# STM32H7S register map
File version: 1.3
CPU: CM7 r0p1, little endian, MPU, FPU, 4 interrupt priority bits
Registers are 32-bit, read-write, reset 0x0 unless marked. A register's access mark holds for its fields unless they carry their own. Offsets are from the block's base; [hi:lo] are bit positions; {n}, {i} and the like mark numbered series.

## TIM16 — General purpose timers
Base 0x42004400
Same registers: TIM17 0x42004800
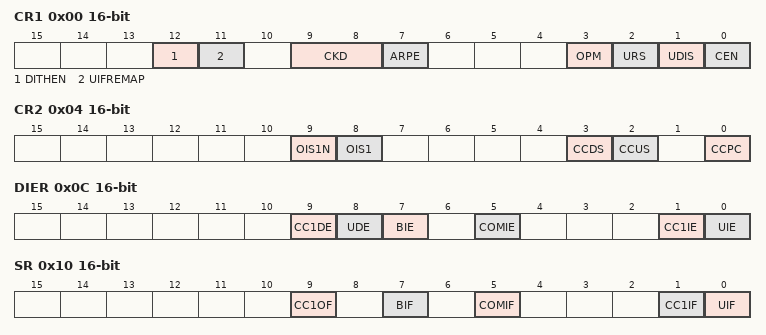
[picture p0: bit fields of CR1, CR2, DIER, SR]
0x00 CR1 16-bit — TIM16 control register 1
  [12] DITHEN — Dithering enable Note: The DITHEN bit can only be modified when CEN bit is reset.
    0=Disabled (Dithering disabled); 1=Enabled (Dithering enabled)
  [11] UIFREMAP — UIF status bit remapping
    0=Disabled (No remapping. UIF status bit is not copied to TIMx_CNT register bit 31); 1=Enabled (Remapping enabled. UIF status bit is copied to TIMx_CNT register bit 31)
  [9:8] CKD — Clock division This bit-field indicates the division ratio between the timer clock (tim_ker_ck) frequency and the dead-time and sampling clock (t<sub>DTS</sub>)used by the dead-time generators and the digital filters (tim_tix),
    0=Div1 (t_DTS = t_CK_INT); 1=Div2 (t_DTS = 2 × t_CK_INT); 2=Div4 (t_DTS = 4 × t_CK_INT)
  [7] ARPE — Auto-reload preload enable
    0=Disabled (TIMx_APRR register is not buffered); 1=Enabled (TIMx_APRR register is buffered)
  [3] OPM — One pulse mode
    0=Disabled (Counter is not stopped at update event); 1=Enabled (Counter stops counting at the next update event (clearing the CEN bit))
  [2] URS — Update request source This bit is set and cleared by software to select the UEV event sources. Counter overflow/underflow Setting the UG bit Update generation through the slave mode controller
    0=AnyEvent (Any of counter overflow/underflow, setting UG, or update through slave mode, generates an update interrupt or DMA request); 1=CounterOnly (Only counter overflow/underflow generates an update interrupt or DMA request)
  [1] UDIS — Update disable This bit is set and cleared by software to enable/disable UEV event generation. Counter overflow/underflow Setting the UG bit Update generation through the slave mode controller Buffered registers are then loaded with their preload values.
    0=Enabled (Update event enabled); 1=Disabled (Update event disabled)
  [0] CEN — Counter enable Note: External clock and gated mode can work only if the CEN bit has been previously set by software. However trigger mode can set the CEN bit automatically by hardware.
    0=Disabled (Counter disabled); 1=Enabled (Counter enabled)
0x04 CR2 16-bit — TIM16 control register 2
  [n+8] OIS{n}N (n=1..1) — Output Idle state (OC{n}N output)
    0=Reset (OCxN=0 after a dead-time when MOE=0); 1=Set (OCxN=1 after a dead-time when MOE=0)
  [n+7] OIS{n} (n=1..1) — Output Idle state (OC{n} output)
    0=Reset (OCx=0 (after a dead-time if OCx(N) is implemented) when MOE=0); 1=Set (OCx=1 (after a dead-time if OCx(N) is implemented) when MOE=0)
  [3] CCDS — Capture/compare DMA selection
    0=OnCompare (CCx DMA request sent when CCx event occurs); 1=OnUpdate (CCx DMA request sent when update event occurs)
  [2] CCUS — Capture/compare control update selection Note: This bit acts only on channels that have a complementary output.
    0=Sw (When capture/compare control bits are preloaded (CCPC=1), they are updated by setting the COMG bit only); 1=SwOrEdge (When capture/compare control bits are preloaded (CCPC=1), they are updated by setting the COMG bit or when an rising edge occurs on TRGI)
  [0] CCPC — Capture/compare preloaded control Note: This bit acts only on channels that have a complementary output.
    0=NotPreloaded (CCxE, CCxNE and OCxM bits are not preloaded); 1=Preloaded (CCxE, CCxNE and OCxM bits are preloaded)
0x0C DIER 16-bit — TIM16 DMA/interrupt enable register
  [n+8] CC{n}DE (n=1..1) — Capture/Compare {n} DMA request enable
    0=Disabled (CCx DMA request disabled); 1=Enabled (CCx DMA request enabled)
  [8] UDE — Update DMA request enable
    0=Disabled (Update DMA request disabled); 1=Enabled (Update DMA request enabled)
  [7] BIE — Break interrupt enable
    0=Disabled (Break interrupt disabled); 1=Enabled (Break interrupt enabled)
  [5] COMIE — COM interrupt enable
    0=Disabled (COM interrupt disabled); 1=Enabled (COM interrupt enabled)
  [n] CC{n}IE (n=1..1) — Capture/Compare {n} interrupt enable
    0=Disabled (CCx interrupt disabled); 1=Enabled (CCx interrupt enabled)
  [0] UIE — Update interrupt enable
    0=Disabled (Update interrupt disabled); 1=Enabled (Update interrupt enabled)
0x10 SR 16-bit — TIM16 status register
  [n+8] CC{n}OF (n=1..1) write-0-clears — Capture/Compare {n} overcapture flag
    on read: 0=No overcapture has been detected; 1=Overcapture (The counter value has been captured in TIMx_CCRx register while CCxIF flag was already set) | on write: 0=Clear flag
  [7] BIF write-0-clears — Break interrupt flag This flag is set by hardware as soon as the tim_brk input goes active. It can be cleared by software if the break input is not active.
    on read: 0=NoTrigger (No break event occurred); 1=Trigger (An active level has been detected on the break input. An interrupt is generated if BIE=1 in the TIMx_DIER register) | on write: 0=Clear flag
  [5] COMIF write-0-clears — COM interrupt flag This flag is set by hardware on a COM event (once the capture/compare control bits CCxE, CCxNE, OCxM have been updated). It is cleared by software.
    on read: 0=No COM event occurred; 1=COM (COM interrupt pending) | on write: 0=Clear flag
  [n] CC{n}IF (n=1..1) write-0-clears — Capture/compare {n} interrupt flag
    on read: 0=NoMatch (No campture/compare has been detected); 1=Match (If CC1 is an output: The content of the counter TIMx_CNT matches the content of the TIMx_CCR1 register. If CC1 is an input: The counter value has been captured in TIMx_CCR1 register.) | on write: 0=Clear flag
  [0] UIF write-0-clears — Update interrupt flag This bit is set by hardware on an update event. It is cleared by software. At overflow regarding the repetition counter value (update if repetition counter = 0) and if the UDIS=0 in the TIMx_CR1 register. When CNT is reinitialized by software using the UG bit in TIMx_EGR register, if URS=0 and UDIS=0 in the TIMx_CR1 register.
    on read: 0=NoUpdateOccurred; 1=UpdatePending (Update interrupt pending) | on write: 0=Clear flag
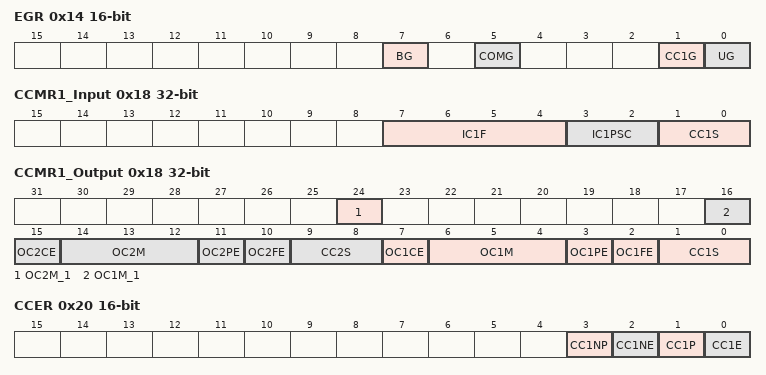
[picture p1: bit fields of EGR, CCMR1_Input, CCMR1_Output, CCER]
0x14 EGR 16-bit wo — TIM16 event generation register
  [7] BG — Break generation This bit is set by software in order to generate an event, it is automatically cleared by hardware.
    1=Trigger (A break event is generated. MOE bit is cleared and BIF flag is set. Related interrupt or DMA transfer can occur if enabled)
  [5] COMG — Capture/Compare control update generation This bit can be set by software, it is automatically cleared by hardware. Note: This bit acts only on channels that have a complementary output.
    1=Trigger (When CCPC bit is set, it allows CCxE, CCxNE and OCxM bits to be updated)
  [n] CC{n}G (n=1..1) — Capture/compare {n} generation
    1=Trigger (If CC1 is an output: CC1IF flag is set, Corresponding interrupt or DMA request is sent if enabled. If CC1 is an input: The current value of the counter is captured in TIMx_CCR1 register.)
  [0] UG — Update generation This bit can be set by software, it is automatically cleared by hardware.
    1=Update (Re-initializes the timer counter and generates an update of the registers.)
0x18 CCMR1_Input — TIM16 capture/compare mode register 1
  [n+6:n+3] IC{n}F (n=1..1) — Input capture {n} filter
    0=No filter, sampling is done at fDTS; 1=FCK_INT_N2 (fSAMPLING=fCK_INT, N=2); 2=FCK_INT_N4 (fSAMPLING=fCK_INT, N=4); 3=FCK_INT_N8 (fSAMPLING=fCK_INT, N=8); 4=FDTS_Div2_N6 (fSAMPLING=fDTS/2, N=6); 5=FDTS_Div2_N8 (fSAMPLING=fDTS/2, N=8); 6=FDTS_Div4_N6 (fSAMPLING=fDTS/4, N=6); 7=FDTS_Div4_N8 (fSAMPLING=fDTS/4, N=8); 8=FDTS_Div8_N6 (fSAMPLING=fDTS/8, N=6); 9=FDTS_Div8_N8 (fSAMPLING=fDTS/8, N=8); 10=FDTS_Div16_N5 (fSAMPLING=fDTS/16, N=5); 11=FDTS_Div16_N6 (fSAMPLING=fDTS/16, N=6); 12=FDTS_Div16_N8 (fSAMPLING=fDTS/16, N=8); 13=FDTS_Div32_N5 (fSAMPLING=fDTS/32, N=5); 14=FDTS_Div32_N6 (fSAMPLING=fDTS/32, N=6); 15=FDTS_Div32_N8 (fSAMPLING=fDTS/32, N=8)
  [n+2:n+1] IC{n}PSC (n=1..1) — Input capture {n} prescaler
    0=No prescaler, capture is done each time an edge is detected on the capture input; 1=TwoEvents (Capture is done once every 2 events); 2=FourEvents (Capture is done once every 4 events); 3=EightEvents (Capture is done once every 8 events)
  [1:0] CC1S — Capture/Compare 1 selection This bit-field defines the direction of the channel (input/output) as well as the used input. Others: Reserved Note: CC1S bits are writable only when the channel is OFF (CC1E = 0 in TIMx_CCER).
    1=TI1 (CC1 channel is configured as input, IC1 is mapped on TI1)
0x18 CCMR1_Output (alternate view of CCMR1_Input) — TIM16 capture/compare mode register 1 [alternate]
  [24] OC2M_1 — OC2M[3]
  [16] OC1M_1 — OC1M[3]
  [8n-1] OC{n}CE (n=1..2) — Output compare {n} clear enable
    0=Disabled (OCxRef is not affected by the ocref_clr_int signal); 1=Enabled (OCxRef is cleared as soon as a High level is detected on ocref_clr_int signal)
  [8n-2:8n-4] OC{n}M (n=1..2) — Output compare {n} mode
    0=Frozen (The comparison between the output compare register TIMx_CCRy and the counter TIMx_CNT has no effect on the outputs); 1=ActiveOnMatch (Set channel to active level on match. OCyREF signal is forced high when the counter matches the capture/compare register); 2=InactiveOnMatch (Set channel to inactive level on match. OCyREF signal is forced low when the counter matches the capture/compare register); 3=Toggle (OCyREF toggles when TIMx_CNT=TIMx_CCRy); 4=ForceInactive (OCyREF is forced low); 5=ForceActive (OCyREF is forced high); 6=PwmMode1 (In upcounting, channel is active as long as TIMx_CNT<TIMx_CCRy else inactive. In downcounting, channel is inactive as long as TIMx_CNT>TIMx_CCRy else active); 7=PwmMode2 (Inversely to PwmMode1)
  [8n-5] OC{n}PE (n=1..2) — Output compare {n} preload enable
    0=Disabled (Preload register on CCRx disabled. New values written to CCRx are taken into account immediately); 1=Enabled (Preload register on CCRx enabled. Preload value is loaded into active register on each update event)
  [8n-6] OC{n}FE (n=1..2) — Output compare {n} fast enable
    0=Disabled (Fast output disabled); 1=Enabled (Fast output enabled)
  [8n-7:8n-8] CC{n}S (n=1..2) — Capture/Compare {n} selection
    0=Output (CCx channel is configured as output)
0x20 CCER 16-bit — TIM16 capture/compare enable register
  [n+2] CC{n}NP (n=1..1) — Capture/Compare {n} output Polarity
    0=ActiveHigh (OCxN active high); 1=ActiveLow (OCxN active low)
  [n+1] CC{n}NE (n=1..1) — Capture/Compare {n} complementary output enable
    0=Disabled (Complementary output disabled); 1=Enabled (Complementary output enabled)
  [n] CC{n}P (n=1..1) — Capture/Compare {n} output Polarity
    0=RisingEdge (Noninverted/rising edge); 1=FallingEdge (Inverted/falling edge)
  [n-1] CC{n}E (n=1..1) — Capture/Compare {n} output enable
    0=Disabled (Capture disabled); 1=Enabled (Capture enabled)
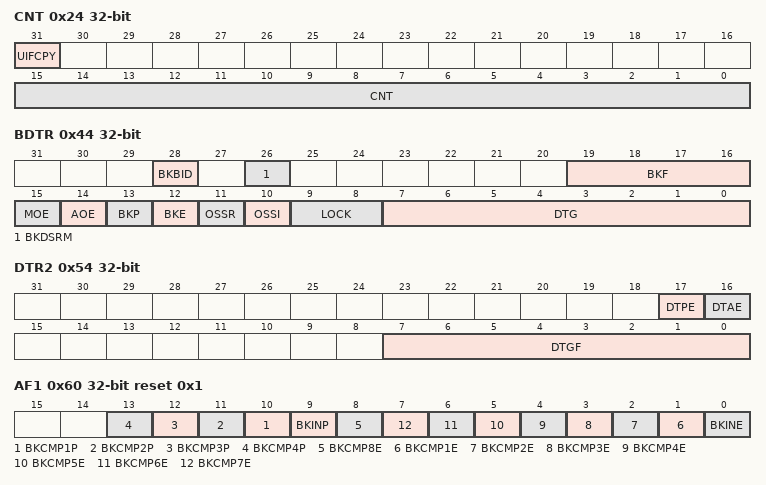
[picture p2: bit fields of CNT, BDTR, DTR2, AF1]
0x24 CNT access per field — TIM16 counter
  [31] UIFCPY ro — UIF Copy This bit is a read-only copy of the UIF bit of the TIMx_ISR register. If the UIFREMAP bit in TIMx_CR1 is reset, bit 31 is reserved.
    0=NoUpdateOccurred; 1=UpdatePending (Update interrupt pending)
  [15:0] CNT rw — Counter value Non-dithering mode (DITHEN = 0) The register holds the counter value. Dithering mode (DITHEN = 1) The register only holds the non-dithered part in CNT[15:0]. The fractional part is not available.
0x28 PSC 16-bit — TIM16 prescaler
  [15:0] PSC — Prescaler value The counter clock frequency (tim_cnt_ck) is equal to f<sub>tim_psc_ck</sub> / (PSC[15:0] + 1). PSC contains the value to be loaded in the active prescaler register at each update event (including when the counter is cleared through UG bit of TIMx_EGR register or through trigger controller when configured in reset mode).
0x2C ARR reset 0xFFFF — TIM16 auto-reload register
  [19:0] ARR — Auto-reload value ARR is the value to be loaded in the actual auto-reload register. Refer to the Section 68.4.3: Time-base unit on page 4032 for more details about ARR update and behavior. The counter is blocked while the auto-reload value is null. Non-dithering mode (DITHEN = 0) The register holds the auto-reload value in ARR[15:0]. The ARR[19:16] bits are reset. Dithering mode (DITHEN = 1) The register holds the integer part in ARR[19:4]. The ARR[3:0] bitfield contains the dithered part.
0x30 RCR 16-bit — TIM16 repetition counter register
  [7:0] REP — Repetition counter reload value This bitfield defines the update rate of the compare registers (i.e. periodic transfers from preload to active registers) when preload registers are enable. It also defines the update interrupt generation rate, if this interrupt is enable. When the repetition down-counter reaches zero, an update event is generated and it restarts counting from REP value. As the repetition counter is reloaded with REP value only at the repetition update event UEV, any write to the TIMx_RCR register is not taken in account until the next repetition update event. It means in PWM mode (REP+1) corresponds to the number of PWM periods in edge-aligned mode: the number of PWM periods in edge-aligned mode the number of half PWM period in center-aligned mode
{0x30+4i} CCR{i} (i=1..1) — capture/compare register
  [19:0] CCR — Capture/Compare value
0x44 BDTR — TIM16 break and dead-time register
  [28] BKBID — Break Bidirectional In the bidirectional mode (BKBID bit set to 1), the break input is configured both in input mode and in open drain output mode. Any active break event asserts a low logic level on the Break input to indicate an internal break event to external devices. Note: This bit cannot be modified as long as LOCK level 1 has been programmed (LOCK bits in TIMx_BDTR register). Note: Any write operation to this bit takes a delay of 1 APB clock cycle to become effective.
  [26] BKDSRM — Break Disarm This bit is cleared by hardware when no break source is active. The BKDSRM bit must be set by software to release the bidirectional output control (open-drain output in Hi-Z state) and then be polled it until it is reset by hardware, indicating that the fault condition has disappeared. Note: Any write operation to this bit takes a delay of 1 APB clock cycle to become effective.
  [19:16] BKF — Break filter This bit-field defines the frequency used to sample tim_brk input and the length of the digital filter applied to tim_brk. The digital filter is made of an event counter in which N events are needed to validate a transition on the output: This bit cannot be modified when LOCK level 1 has been programmed (LOCK bits in TIMx_BDTR register).
  [15] MOE — Main output enable This bit is cleared asynchronously by hardware as soon as the tim_brk input is active. It is set by software or automatically depending on the AOE bit. It is acting only on the channels which are configured in output. See tim_oc1/tim_oc1n enable description for more details (Section 68.8.8: TIMx capture/compare enable register (TIMx_CCER)(x = 16 to 17) on page 4111).
    0=DisabledIdle (OC/OCN are disabled or forced idle depending on OSSI); 1=Enabled (OC/OCN are enabled if CCxE/CCxNE are set)
  [14] AOE — Automatic output enable Note: This bit can not be modified as long as LOCK level 1 has been programmed (LOCK bits in TIMx_BDTR register).
    0=Manual (MOE can be set only by software); 1=Automatic (MOE can be set by software or automatically at the next update event (if none of the break inputs BRK and BRK2 is active))
  [13] BKP — Break polarity Note: This bit can not be modified as long as LOCK level 1 has been programmed (LOCK bits in TIMx_BDTR register). Note: Any write operation to this bit takes a delay of 1 APB clock cycle to become effective.
    0=ActiveLow (Break input BRKx is active low); 1=ActiveHigh (Break input BRKx is active high)
  [12] BKE — Break enable 1; Break inputs (tim_brk and tim_sys_brk event) enabled Note: This bit cannot be modified when LOCK level 1 has been programmed (LOCK bits in TIMx_BDTR register). Note: Any write operation to this bit takes a delay of 1 APB clock cycle to become effective.
    0=Disabled (Break function x disabled); 1=Enabled (Break function x enabled)
  [11] OSSR — Off-state selection for Run mode This bit is used when MOE=1 on channels that have a complementary output which are configured as outputs. OSSR is not implemented if no complementary output is implemented in the timer. See tim_oc1/tim_oc1n enable description for more details (Section 68.8.8: TIMx capture/compare enable register (TIMx_CCER)(x = 16 to 17) on page 4111). Note: This bit can not be modified as soon as the LOCK level 2 has been programmed (LOCK bits in TIMx_BDTR register).
    0=HiZ (When inactive, OC/OCN outputs are disabled); 1=IdleLevel (When inactive, OC/OCN outputs are enabled with their inactive level)
  [10] OSSI — Off-state selection for Idle mode This bit is used when MOE=0 on channels configured as outputs. See tim_oc1/tim_oc1n enable description for more details (Section 68.8.8: TIMx capture/compare enable register (TIMx_CCER)(x = 16 to 17) on page 4111). Note: This bit can not be modified as soon as the LOCK level 2 has been programmed (LOCK bits in TIMx_BDTR register).
    0=HiZ (When inactive, OC/OCN outputs are disabled); 1=IdleLevel (When inactive, OC/OCN outputs are forced to idle level)
  [9:8] LOCK — Lock configuration These bits offer a write protection against software errors. Note: The LOCK bits can be written only once after the reset. Once the TIMx_BDTR register has been written, their content is frozen until the next reset.
    0=Off (No bit is write protected); 1=Level1 (Any bits except MOE, OSSR, OSSI and LOCK in TIMx_BDTR register, OISx and OISxN bits in TIMx_CR2 register can no longer be written); 2=Level2 (LOCK Level 1 + CC Polarity bits (CCxP/CCxNP bits in TIMx_CCER register, as long as the related channel is configured in output through the CCxS bits) as well as OSSR and OSSI bits can no longer be written); 3=Level3 (LOCK Level 2 + CC Control bits (OCxM and OCxPE bits in TIMx_CCMRx registers, as long as the related channel is configured in output through the CCxS bits) can no longer be written)
  [7:0] DTG — Dead-time generator setup This bit-field defines the duration of the dead-time inserted between the complementary outputs. DT correspond to this duration. DTG[7:5]=0xx => DT=DTG[7:0]x t<sub>dtg</sub> with t<sub>dtg</sub>=t<sub>DTS</sub> DTG[7:5]=10x => DT=(64+DTG[5:0])xt<sub>dtg</sub> with T<sub>dtg</sub>=2xt<sub>DTS</sub> DTG[7:5]=110 => DT=(32+DTG[4:0])xt<sub>dtg</sub> with T<sub>dtg</sub>=8xt<sub>DTS</sub> DTG[7:5]=111 => DT=(32+DTG[4:0])xt<sub>dtg</sub> with T<sub>dtg</sub>=16xt<sub>DTS</sub> Example if T<sub>DTS</sub>=125ns (8MHz), dead-time possible values are: 0 to 15875 ns by 125 ns steps, 16 s to 31750 ns by 250 ns steps, 32 s to 63 s by 1 s steps, 64 s to 126 s by 2 s steps Note: This bit-field can not be modified as long as LOCK level 1, 2 or 3 has been programmed (LOCK bits in TIMx_BDTR register).
0x54 DTR2 — TIM16 timer deadtime register 2
  [17] DTPE — Deadtime preload enable Note: This bit can not be modified as long as LOCK level 1, 2 or 3 has been programmed (LOCK bits in TIMx_BDTR register).
  [16] DTAE — Deadtime asymmetric enable Note: This bit can not be modified as long as LOCK level 1, 2 or 3 has been programmed (LOCK bits in TIMx_BDTR register).
  [7:0] DTGF — Dead-time falling edge generator setup This bit-field defines the duration of the dead-time inserted between the complementary outputs, on the falling edge. DTGF[7:5]=0xx => DTF=DTGF[7:0]x t<sub>dtg</sub> with t<sub>dtg</sub>=t<sub>DTS</sub>. DTGF[7:5]=10x => DTF=(64+DTGF[5:0])xt<sub>dtg</sub> with T<sub>dtg</sub>=2xt<sub>DTS</sub>. DTGF[7:5]=110 => DTF=(32+DTGF[4:0])xt<sub>dtg</sub> with T<sub>dtg</sub>=8xt<sub>DTS</sub>. DTGF[7:5]=111 => DTF=(32+DTGF[4:0])xt<sub>dtg</sub> with T<sub>dtg</sub>=16xt<sub>DTS</sub>. Example if T<sub>DTS</sub>=125ns (8MHz), dead-time possible values are: 0 to 15875 ns by 125 ns steps, 16 us to 31750 ns by 250 ns steps, 32 us to 63us by 1 us steps, 64 us to 126 us by 2 us steps Note: This bit-field can not be modified as long as LOCK level 1, 2 or 3 has been programmed (LOCK bits in TIMx_BDTR register).
0x5C TISEL — TIM16 input selection register
  [3:0] TI1SEL — selects tim_ti1_in[15:0] input ... Refer to Section 68.4.2: TIM15/TIM16/TIM17 pins and internal signals for interconnects list.
0x60 AF1 reset 0x1 — TIM16 alternate function register 1
  [n+9] BKCMP{n}P (n=1..4) — tim_brk_cmp{n} input polarity This bit selects the tim_brk_cmp{n} input sensitivity. It must be programmed together with the BKP polarity bit. Note: This bit can not be modified as long as LOCK level 1 has been programmed (LOCK bits in TIMx_BDTR register).
  [9] BKINP — TIMx_BKIN input polarity This bit selects the TIMx_BKIN alternate function input sensitivity. It must be programmed together with the BKP polarity bit. Note: This bit can not be modified as long as LOCK level 1 has been programmed (LOCK bits in TIMx_BDTR register).
  [8] BKCMP8E — tim_brk_cmp8 enable This bit enables the tim_brk_cmp8 for the timers tim_brk input. mdf_brkx output is ORed with the other tim_brk sources. Note: This bit can not be modified as long as LOCK level 1 has been programmed (LOCK bits in TIMx_BDTR register).
  [n] BKCMP{n}E (n=1..7) — tim_brk_cmp{n} enable This bit enables the tim_brk_cmp{n} for the timers tim_brk input. tim_brk_cmp{n} output is ORed with the other tim_brk sources. Note: This bit can not be modified as long as LOCK level 1 has been programmed (LOCK bits in TIMx_BDTR register).
  [0] BKINE — TIMx_BKIN input enable This bit enables the TIMx_BKIN alternate function input for the timers tim_brk input. TIMx_BKIN input is ORed with the other tim_brk sources. Note: This bit can not be modified as long as LOCK level 1 has been programmed (LOCK bits in TIMx_BDTR register).
0x64 AF2 — TIM16 alternate function register 2
  [18:16] OCRSEL — tim_ocref_clr source selection These bits select the tim_ocref_clr input source. Refer to Section 68.4.2: TIM15/TIM16/TIM17 pins and internal signals for product specific implementation. Note: These bits can not be modified as long as LOCK level 1 has been programmed (LOCK bits in TIMx_BDTR register).
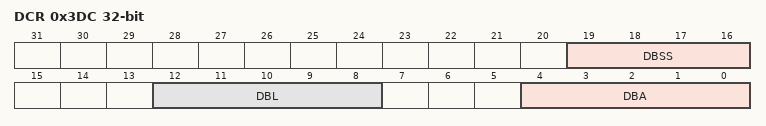
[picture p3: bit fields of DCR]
0x3DC DCR — TIM16 DMA control register
  [19:16] DBSS — DMA burst source selection This bitfield defines the interrupt source that triggers the DMA burst transfers (the timer recognizes a burst transfer when a read or a write access is done to the TIMx_DMAR address). Other: reserved
  [12:8] DBL — DMA burst length This 5-bit field defines the length of DMA transfers (the timer recognizes a burst transfer when a read or a write access is done to the TIMx_DMAR address), i.e. the number of transfers. Transfers can be in half-words or in bytes (see example below). ...
  [4:0] DBA — DMA base address This 5-bit field defines the base-address for DMA transfers (when read/write access are done through the TIMx_DMAR address). DBA is defined as an offset starting from the address of the TIMx_CR1 register. Example: ... Example: Let us consider the following transfer: DBL = 7 transfers and DBA = TIMx_CR1. In this case the transfer is done to/from 7 registers starting from the TIMx_CR1 address.
0x3E0 DMAR — TIM16/TIM17 DMA address for full transfer
  [31:0] DMAB — DMA register for burst accesses A read or write operation to the DMAR register accesses the register located at the address (TIMx_CR1 address) + (DBA + DMA index) x 4 where TIMx_CR1 address is the address of the control register 1, DBA is the DMA base address configured in TIMx_DCR register, DMA index is automatically controlled by the DMA transfer, and ranges from 0 to DBL (DBL configured in TIMx_DCR).
